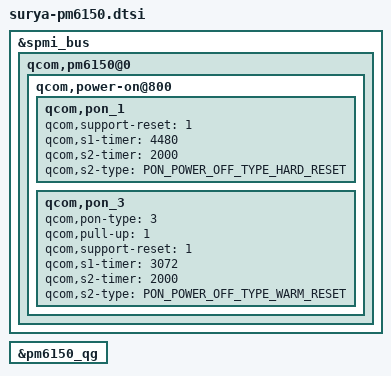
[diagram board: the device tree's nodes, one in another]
&spmi_bus {
	qcom,pm6150@0 {
		qcom,power-on@800 {
			qcom,pon_1 {
				qcom,support-reset = <1>;
				qcom,s1-timer = <4480>;
				qcom,s2-timer = <2000>;
				qcom,s2-type = <PON_POWER_OFF_TYPE_HARD_RESET>;
			};

			qcom,pon_3 {
				qcom,pon-type = <3>;
				qcom,pull-up = <1>;
				qcom,support-reset = <1>;
				qcom,s1-timer = <3072>;
				qcom,s2-timer = <2000>;
				qcom,s2-type = <PON_POWER_OFF_TYPE_WARM_RESET>;
			};
		};
	};
};

&pm6150_qg {
	/delete-property/ qcom,vbatt-cutoff-mv;
	/delete-property/ qcom,vbatt-low-mv;
	/delete-property/ qcom,vbatt-low-cold-mv;
	/delete-property/ qcom,vbatt-empty-mv;
	/delete-property/ qcom,vbatt-empty-cold-mv;
	/delete-property/ qcom,s3-entry-fifo-length;
};
